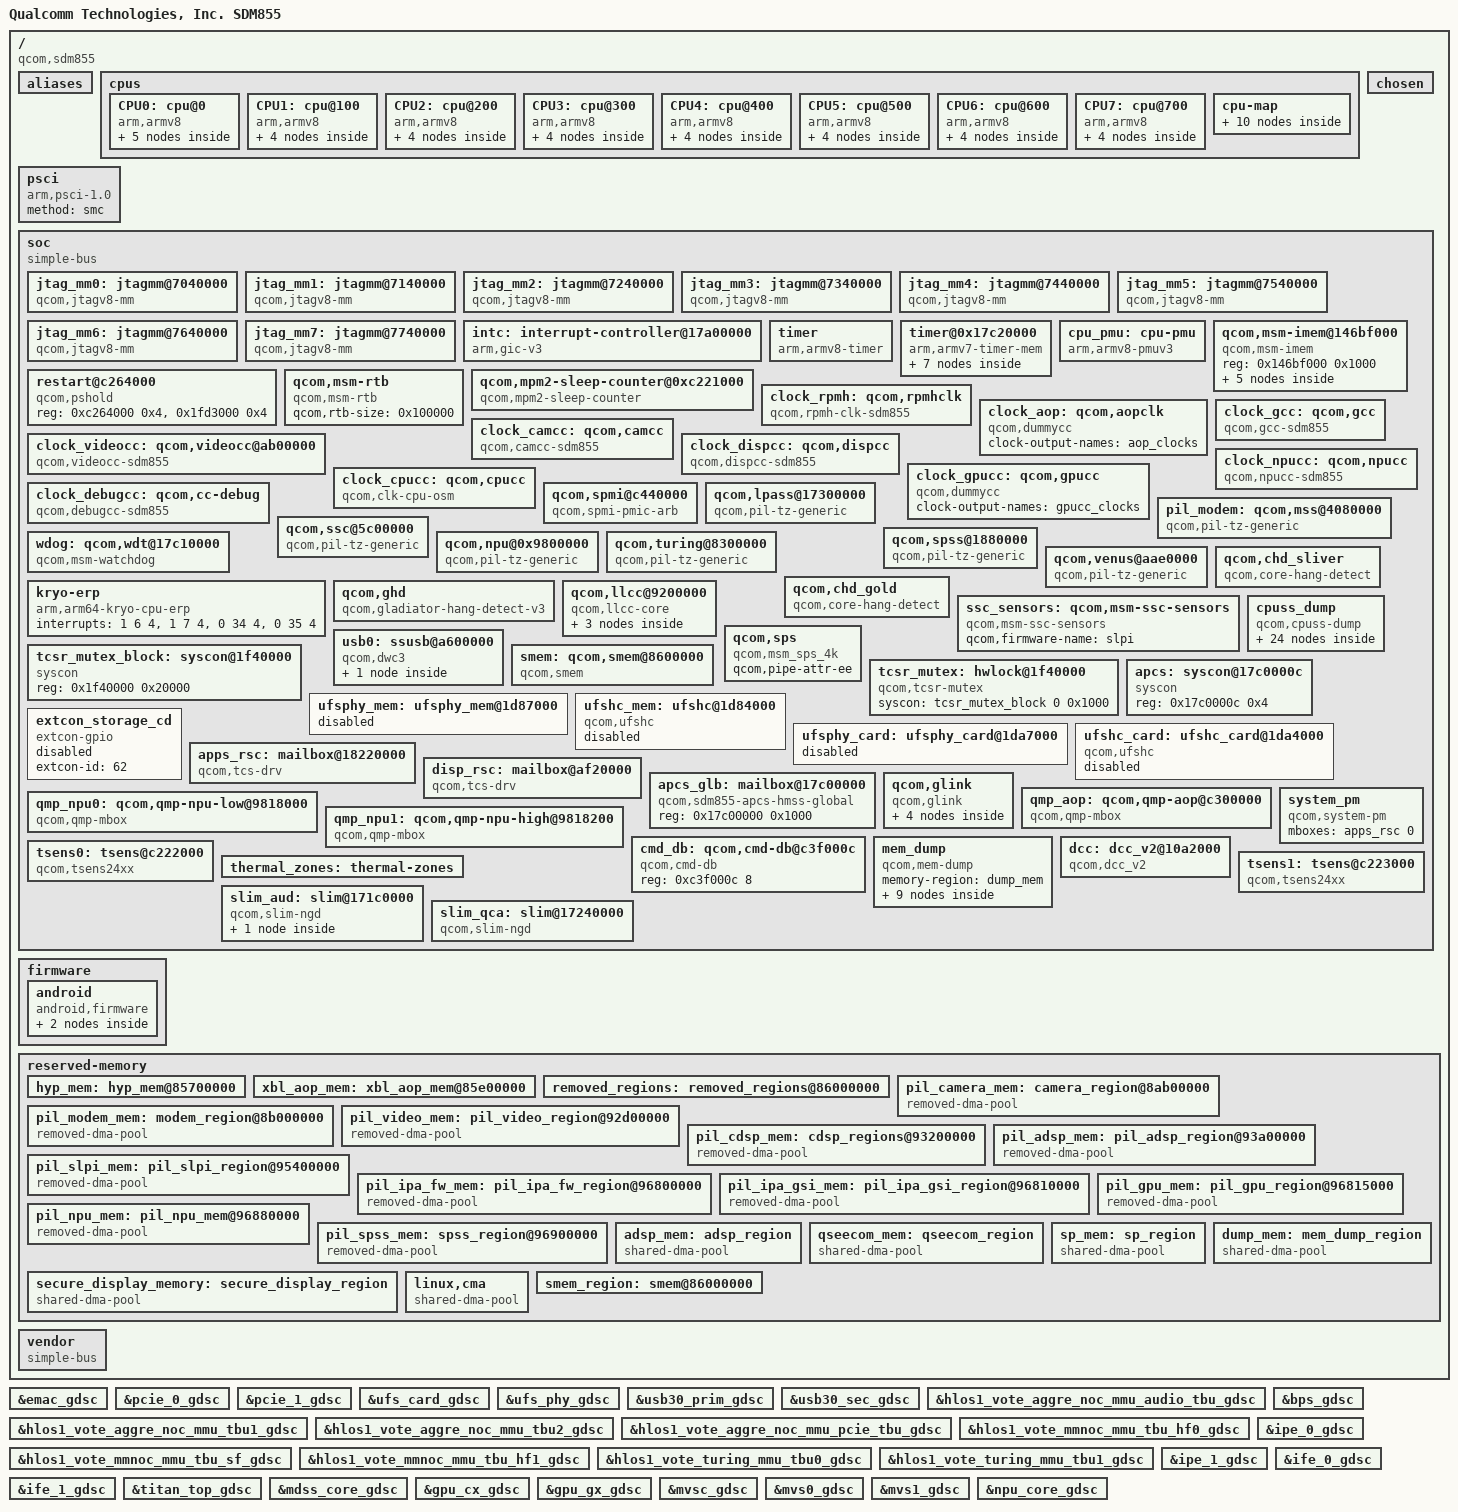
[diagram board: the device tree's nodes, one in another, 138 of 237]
/* Copyright (c) 2017, The Linux Foundation. All rights reserved.
 *
 * This program is free software; you can redistribute it and/or modify
 * it under the terms of the GNU General Public License version 2 and
 * only version 2 as published by the Free Software Foundation.
 *
 * This program is distributed in the hope that it will be useful,
 * but WITHOUT ANY WARRANTY; without even the implied warranty of
 * MERCHANTABILITY or FITNESS FOR A PARTICULAR PURPOSE.  See the
 * GNU General Public License for more details.
 */

#include "skeleton64.dtsi"
#include <dt-bindings/clock/qcom,gcc-sdm855.h>
#include <dt-bindings/clock/qcom,camcc-sdm855.h>
#include <dt-bindings/clock/qcom,dispcc-sdm855.h>
#include <dt-bindings/clock/qcom,gpucc-sdm855.h>
#include <dt-bindings/clock/qcom,videocc-sdm855.h>
#include <dt-bindings/clock/qcom,cpucc-sdm855.h>
#include <dt-bindings/clock/qcom,npucc-sdm855.h>
#include <dt-bindings/clock/qcom,rpmh.h>
#include <dt-bindings/clock/qcom,aop-qmp.h>
#include <dt-bindings/regulator/qcom,rpmh-regulator.h>
#include <dt-bindings/interrupt-controller/arm-gic.h>
#include <dt-bindings/soc/qcom,tcs-mbox.h>
#include <dt-bindings/soc/qcom,dcc_v2.h>

/ {
	model = "Qualcomm Technologies, Inc. SDM855";
	compatible = "qcom,sdm855";
	qcom,msm-id = <339 0x0>;
	interrupt-parent = <&intc>;

	aliases {
		ufshc1 = &ufshc_mem; /* Embedded UFS slot */
		ufshc2 = &ufshc_card; /* Removable UFS slot */
	};

	aliases {
		serial0 = &qupv3_se12_2uart;
		hsuart0 = &qupv3_se17_4uart;
	};

	cpus {
		#address-cells = <2>;
		#size-cells = <0>;

		CPU0: cpu@0 {
			device_type = "cpu";
			compatible = "arm,armv8";
			reg = <0x0 0x0>;
			enable-method = "psci";
			cache-size = <0x8000>;
			next-level-cache = <&L2_0>;
			L2_0: l2-cache {
			      compatible = "arm,arch-cache";
			      cache-size = <0x20000>;
			      cache-level = <2>;
			      next-level-cache = <&L3_0>;

				L3_0: l3-cache {
				      compatible = "arm,arch-cache";
				      cache-size = <0x200000>;
				      cache-level = <3>;
				};
			};

			L1_I_0: l1-icache {
				compatible = "arm,arch-cache";
				qcom,dump-size = <0xa000>;
			};

			L1_D_0: l1-dcache {
				compatible = "arm,arch-cache";
				qcom,dump-size = <0xa000>;
			};

			L1_TLB_0: l1-tlb {
				qcom,dump-size = <0x3000>;
			};
		};

		CPU1: cpu@100 {
			device_type = "cpu";
			compatible = "arm,armv8";
			reg = <0x0 0x100>;
			enable-method = "psci";
			cache-size = <0x8000>;
			next-level-cache = <&L2_1>;
			L2_1: l2-cache {
			      compatible = "arm,arch-cache";
			      cache-size = <0x20000>;
			      cache-level = <2>;
			      next-level-cache = <&L3_0>;
			};

			L1_I_100: l1-icache {
				compatible = "arm,arch-cache";
				qcom,dump-size = <0xa000>;
			};

			L1_D_100: l1-dcache {
				compatible = "arm,arch-cache";
				qcom,dump-size = <0xa000>;
			};

			L1_TLB_100: l1-tlb {
				qcom,dump-size = <0x3000>;
			};
		};

		CPU2: cpu@200 {
			device_type = "cpu";
			compatible = "arm,armv8";
			reg = <0x0 0x200>;
			enable-method = "psci";
			cache-size = <0x8000>;
			next-level-cache = <&L2_2>;
			L2_2: l2-cache {
			      compatible = "arm,arch-cache";
			      cache-size = <0x20000>;
			      cache-level = <2>;
			      next-level-cache = <&L3_0>;
			};

			L1_I_200: l1-icache {
				compatible = "arm,arch-cache";
				qcom,dump-size = <0xa000>;
			};

			L1_D_200: l1-dcache {
				compatible = "arm,arch-cache";
				qcom,dump-size = <0xa000>;
			};

			L1_TLB_200: l1-tlb {
				qcom,dump-size = <0x3000>;
			};
		};

		CPU3: cpu@300 {
			device_type = "cpu";
			compatible = "arm,armv8";
			reg = <0x0 0x300>;
			enable-method = "psci";
			cache-size = <0x8000>;
			next-level-cache = <&L2_3>;
			L2_3: l2-cache {
			      compatible = "arm,arch-cache";
			      cache-size = <0x20000>;
			      cache-level = <2>;
			      next-level-cache = <&L3_0>;
			};

			L1_I_300: l1-icache {
				compatible = "arm,arch-cache";
				qcom,dump-size = <0xa000>;
			};

			L1_D_300: l1-dcache {
				compatible = "arm,arch-cache";
				qcom,dump-size = <0xa000>;
			};

			L1_TLB_300: l1-tlb {
				qcom,dump-size = <0x3000>;
			};
		};

		CPU4: cpu@400 {
			device_type = "cpu";
			compatible = "arm,armv8";
			reg = <0x0 0x400>;
			enable-method = "psci";
			cache-size = <0x20000>;
			next-level-cache = <&L2_4>;
			L2_4: l2-cache {
			      compatible = "arm,arch-cache";
			      cache-size = <0x40000>;
			      cache-level = <2>;
			      next-level-cache = <&L3_0>;
			};

			L1_I_400: l1-icache {
				compatible = "arm,arch-cache";
				qcom,dump-size = <0x14000>;
			};

			L1_D_400: l1-dcache {
				compatible = "arm,arch-cache";
				qcom,dump-size = <0x14000>;
			};

			L1_TLB_400: l1-tlb {
				qcom,dump-size = <0x3c00>;
			};
		};

		CPU5: cpu@500 {
			device_type = "cpu";
			compatible = "arm,armv8";
			reg = <0x0 0x500>;
			enable-method = "psci";
			cache-size = <0x20000>;
			next-level-cache = <&L2_5>;
			L2_5: l2-cache {
			      compatible = "arm,arch-cache";
			      cache-size = <0x40000>;
			      cache-level = <2>;
			      next-level-cache = <&L3_0>;
			};

			L1_I_500: l1-icache {
				compatible = "arm,arch-cache";
				qcom,dump-size = <0x14000>;
			};

			L1_D_500: l1-dcache {
				compatible = "arm,arch-cache";
				qcom,dump-size = <0x14000>;
			};

			L1_TLB_500: l1-tlb {
				qcom,dump-size = <0x3c00>;
			};
		};

		CPU6: cpu@600 {
			device_type = "cpu";
			compatible = "arm,armv8";
			reg = <0x0 0x600>;
			enable-method = "psci";
			cache-size = <0x20000>;
			next-level-cache = <&L2_6>;
			L2_6: l2-cache {
			      compatible = "arm,arch-cache";
			      cache-size = <0x40000>;
			      cache-level = <2>;
			      next-level-cache = <&L3_0>;
			};

			L1_I_600: l1-icache {
				compatible = "arm,arch-cache";
				qcom,dump-size = <0x14000>;
			};

			L1_D_600: l1-dcache {
				compatible = "arm,arch-cache";
				qcom,dump-size = <0x14000>;
			};

			L1_TLB_600: l1-tlb {
				qcom,dump-size = <0x3c00>;
			};
		};

		CPU7: cpu@700 {
			device_type = "cpu";
			compatible = "arm,armv8";
			reg = <0x0 0x700>;
			enable-method = "psci";
			cache-size = <0x20000>;
			next-level-cache = <&L2_7>;
			L2_7: l2-cache {
			      compatible = "arm,arch-cache";
			      cache-size = <0x80000>;
			      cache-level = <2>;
			      next-level-cache = <&L3_0>;
			};

			L1_I_700: l1-icache {
				compatible = "arm,arch-cache";
				qcom,dump-size = <0x14000>;
			};

			L1_D_700: l1-dcache {
				compatible = "arm,arch-cache";
				qcom,dump-size = <0x14000>;
			};

			L1_TLB_700: l1-tlb {
				qcom,dump-size = <0x3c00>;
			};
		};

		cpu-map {
			cluster0 {
				core0 {
					cpu = <&CPU0>;
				};

				core1 {
					cpu = <&CPU1>;
				};

				core2 {
					cpu = <&CPU2>;
				};

				core3 {
					cpu = <&CPU3>;
				};
			};

			cluster1 {
				core0 {
					cpu = <&CPU4>;
				};

				core1 {
					cpu = <&CPU5>;
				};

				core2 {
					cpu = <&CPU6>;
				};

				core3 {
					cpu = <&CPU7>;
				};
			};
		};
	};

	psci {
		compatible = "arm,psci-1.0";
		method = "smc";
	};

	chosen {
		bootargs = "rcupdate.rcu_expedited=1 rcu_nocbs=0-7";
	};

	soc: soc { };

	firmware: firmware {
		android {
			compatible = "android,firmware";
			fstab {
				compatible = "android,fstab";
				vendor {
					compatible = "android,vendor";
					dev = "/dev/block/platform/soc/1d84000.ufshc/by-name/vendor";
					type = "ext4";
					mnt_flags = "ro,barrier=1,discard";
					fsmgr_flags = "wait,slotselect";
					status = "ok";
				};
			};
		};
	};

	reserved-memory {
		#address-cells = <2>;
		#size-cells = <2>;
		ranges;

		hyp_mem: hyp_mem@85700000 {
			no-map;
			reg = <0x0 0x85700000 0x0 0x600000>;
		};

		xbl_aop_mem: xbl_aop_mem@85e00000 {
			no-map;
			reg = <0x0 0x85e00000 0x0 0x140000>;
		};

		removed_regions: removed_regions@86000000 {
			no-map;
			reg = <0x0 0x86200000 0x0 0x2d00000>;
		};

		pil_camera_mem: camera_region@8ab00000 {
			compatible = "removed-dma-pool";
			no-map;
			reg = <0x0 0x8ab00000 0x0 0x500000>;
		};

		pil_modem_mem: modem_region@8b000000 {
			compatible = "removed-dma-pool";
			no-map;
			reg = <0x0 0x8b000000 0x0 0x7D00000>;
		};

		pil_video_mem: pil_video_region@92d00000 {
			compatible = "removed-dma-pool";
			no-map;
			reg = <0x0 0x92d00000 0x0 0x500000>;
		};

		pil_cdsp_mem: cdsp_regions@93200000 {
			compatible = "removed-dma-pool";
			no-map;
			reg = <0x0 0x93200000 0x0 0x800000>;
		};

		pil_adsp_mem: pil_adsp_region@93a00000 {
			compatible = "removed-dma-pool";
			no-map;
			reg = <0x0 0x93a00000 0x0 0x1a00000>;
		};

		pil_slpi_mem: pil_slpi_region@95400000 {
			compatible = "removed-dma-pool";
			no-map;
			reg = <0x0 0x95400000 0x0 0x1400000>;
		};

		pil_ipa_fw_mem: pil_ipa_fw_region@96800000 {
			compatible = "removed-dma-pool";
			no-map;
			reg = <0x0 0x96800000 0x0 0x10000>;
		};

		pil_ipa_gsi_mem: pil_ipa_gsi_region@96810000 {
			compatible = "removed-dma-pool";
			no-map;
			reg = <0x0 0x96810000 0x0 0x5000>;
		};

		pil_gpu_mem: pil_gpu_region@96815000 {
			compatible = "removed-dma-pool";
			no-map;
			reg = <0x0 0x96815000 0x0 0x1000>;
		};

		pil_npu_mem: pil_npu_mem@96880000 {
			compatible = "removed-dma-pool";
			no-map;
			reg = <0x0 0x96880000 0x0 0x80000>;
		};

		pil_spss_mem: spss_region@96900000 {
			compatible = "removed-dma-pool";
			no-map;
			reg = <0x0 0x96900000 0x0 0x100000>;
		};

		adsp_mem: adsp_region {
			compatible = "shared-dma-pool";
			alloc-ranges = <0x0 0x00000000 0x0 0xffffffff>;
			reusable;
			alignment = <0x0 0x400000>;
			size = <0x0 0xc00000>;
		};

		qseecom_mem: qseecom_region {
			compatible = "shared-dma-pool";
			alloc-ranges = <0x0 0x00000000 0x0 0xffffffff>;
			reusable;
			alignment = <0x0 0x400000>;
			size = <0x0 0x1400000>;
		};

		sp_mem: sp_region {  /* SPSS-HLOS ION shared mem */
			compatible = "shared-dma-pool";
			alloc-ranges = <0x0 0x00000000 0x0 0xffffffff>;
			reusable;
			alignment = <0x0 0x400000>;
			size = <0x0 0x800000>;
		};

		secure_display_memory: secure_display_region {
			compatible = "shared-dma-pool";
			alloc-ranges = <0x0 0x00000000 0x0 0xffffffff>;
			reusable;
			alignment = <0x0 0x400000>;
			size = <0x0 0x5c00000>;
		};

		dump_mem: mem_dump_region {
			compatible = "shared-dma-pool";
			reusable;
			size = <0 0x2400000>;
		};

		/* global autoconfigured region for contiguous allocations */
		linux,cma {
			compatible = "shared-dma-pool";
			alloc-ranges = <0x0 0x00000000 0x0 0xffffffff>;
			reusable;
			alignment = <0x0 0x400000>;
			size = <0x0 0x2000000>;
			linux,cma-default;
		};

		smem_region: smem@86000000 {
			no-map;
			reg = <0x0 0x86000000 0x0 0x200000>;
		};
	};

	vendor: vendor {
		#address-cells = <1>;
		#size-cells = <1>;
		ranges = <0 0 0 0xffffffff>;
		compatible = "simple-bus";
	};
};

#include "sdm855-gdsc.dtsi"

#include "sdm855-sde-pll.dtsi"
#include "sdm855-sde.dtsi"
#include "sdm855-sde-display.dtsi"

&soc {
	#address-cells = <1>;
	#size-cells = <1>;
	ranges = <0 0 0 0xffffffff>;
	compatible = "simple-bus";

	jtag_mm0: jtagmm@7040000 {
		compatible = "qcom,jtagv8-mm";
		reg = <0x7040000 0x1000>;
		reg-names = "etm-base";

		clocks = <&clock_aop QDSS_CLK>;
		clock-names = "core_clk";

		qcom,coresight-jtagmm-cpu = <&CPU0>;
	};

	jtag_mm1: jtagmm@7140000 {
		compatible = "qcom,jtagv8-mm";
		reg = <0x7140000 0x1000>;
		reg-names = "etm-base";

		clocks = <&clock_aop QDSS_CLK>;
		clock-names = "core_clk";

		qcom,coresight-jtagmm-cpu = <&CPU1>;
	};

	jtag_mm2: jtagmm@7240000 {
		compatible = "qcom,jtagv8-mm";
		reg = <0x7240000 0x1000>;
		reg-names = "etm-base";

		clocks = <&clock_aop QDSS_CLK>;
		clock-names = "core_clk";

		qcom,coresight-jtagmm-cpu = <&CPU2>;
	};

	jtag_mm3: jtagmm@7340000 {
		compatible = "qcom,jtagv8-mm";
		reg = <0x7340000 0x1000>;
		reg-names = "etm-base";

		clocks = <&clock_aop QDSS_CLK>;
		clock-names = "core_clk";

		qcom,coresight-jtagmm-cpu = <&CPU3>;
	};

	jtag_mm4: jtagmm@7440000 {
		compatible = "qcom,jtagv8-mm";
		reg = <0x7440000 0x1000>;
		reg-names = "etm-base";

		clocks = <&clock_aop QDSS_CLK>;
		clock-names = "core_clk";

		qcom,coresight-jtagmm-cpu = <&CPU4>;
	};

	jtag_mm5: jtagmm@7540000 {
		compatible = "qcom,jtagv8-mm";
		reg = <0x7540000 0x1000>;
		reg-names = "etm-base";

		clocks = <&clock_aop QDSS_CLK>;
		clock-names = "core_clk";

		qcom,coresight-jtagmm-cpu = <&CPU5>;
	};

	jtag_mm6: jtagmm@7640000 {
		compatible = "qcom,jtagv8-mm";
		reg = <0x7640000 0x1000>;
		reg-names = "etm-base";

		clocks = <&clock_aop QDSS_CLK>;
		clock-names = "core_clk";

		qcom,coresight-jtagmm-cpu = <&CPU6>;
	};

	jtag_mm7: jtagmm@7740000 {
		compatible = "qcom,jtagv8-mm";
		reg = <0x7740000 0x1000>;
		reg-names = "etm-base";

		clocks = <&clock_aop QDSS_CLK>;
		clock-names = "core_clk";

		qcom,coresight-jtagmm-cpu = <&CPU7>;
	};

	intc: interrupt-controller@17a00000 {
		compatible = "arm,gic-v3";
		#interrupt-cells = <3>;
		interrupt-controller;
		#redistributor-regions = <1>;
		redistributor-stride = <0x0 0x20000>;
		reg = <0x17a00000 0x10000>,     /* GICD */
		      <0x17a60000 0x100000>;    /* GICR * 8 */
		interrupts = <1 9 4>;
	};

	timer {
		compatible = "arm,armv8-timer";
		interrupts = <1 1 0xf08>,
			     <1 2 0xf08>,
			     <1 3 0xf08>,
			     <1 0 0xf08>;
		clock-frequency = <19200000>;
	};

	timer@0x17c20000{
		#address-cells = <1>;
		#size-cells = <1>;
		ranges;
		compatible = "arm,armv7-timer-mem";
		reg = <0x17c20000 0x1000>;
		clock-frequency = <19200000>;

		frame@0x17c21000 {
			frame-number = <0>;
			interrupts = <0 7 0x4>,
				     <0 6 0x4>;
			reg = <0x17c21000 0x1000>,
			      <0x17c22000 0x1000>;
		};

		frame@17c23000 {
			frame-number = <1>;
			interrupts = <0 8 0x4>;
			reg = <0x17c23000 0x1000>;
			status = "disabled";
		};

		frame@17c25000 {
			frame-number = <2>;
			interrupts = <0 9 0x4>;
			reg = <0x17c25000 0x1000>;
			status = "disabled";
		};

		frame@17c27000 {
			frame-number = <3>;
			interrupts = <0 10 0x4>;
			reg = <0x17c26000 0x1000>;
			status = "disabled";
		};

		frame@17c29000 {
			frame-number = <4>;
			interrupts = <0 11 0x4>;
			reg = <0x17c29000 0x1000>;
			status = "disabled";
		};

		frame@17c2b000 {
			frame-number = <5>;
			interrupts = <0 12 0x4>;
			reg = <0x17c2b000 0x1000>;
			status = "disabled";
		};

		frame@17c2d000 {
			frame-number = <6>;
			interrupts = <0 13 0x4>;
			reg = <0x17c2d000 0x1000>;
			status = "disabled";
		};
	};

	cpu_pmu: cpu-pmu {
		compatible = "arm,armv8-pmuv3";
		qcom,irq-is-percpu;
		interrupts = <1 5 4>;
	};

	qcom,msm-imem@146bf000 {
		compatible = "qcom,msm-imem";
		reg = <0x146bf000 0x1000>;
		ranges = <0x0 0x146bf000 0x1000>;
		#address-cells = <1>;
		#size-cells = <1>;

		mem_dump_table@10 {
			compatible = "qcom,msm-imem-mem_dump_table";
			reg = <0x10 8>;
		};

		restart_reason@65c {
			compatible = "qcom,msm-imem-restart_reason";
			reg = <0x65c 4>;
		};

		boot_stats@6b0 {
			compatible = "qcom,msm-imem-boot_stats";
			reg = <0x6b0 32>;
		};

		kaslr_offset@6d0 {
			compatible = "qcom,msm-imem-kaslr_offset";
			reg = <0x6d0 12>;
		};

		pil@94c {
			compatible = "qcom,msm-imem-pil";
			reg = <0x94c 200>;
		};
	};

	restart@c264000 {
		compatible = "qcom,pshold";
		reg = <0xc264000 0x4>,
		      <0x1fd3000 0x4>;
		reg-names = "pshold-base", "tcsr-boot-misc-detect";
	};

	qcom,msm-rtb {
		compatible = "qcom,msm-rtb";
		qcom,rtb-size = <0x100000>;
	};

	qcom,mpm2-sleep-counter@0xc221000 {
		compatible = "qcom,mpm2-sleep-counter";
		reg = <0xc221000 0x1000>;
		clock-frequency = <32768>;
	};

	clock_rpmh: qcom,rpmhclk {
		compatible = "qcom,rpmh-clk-sdm855";
		mboxes = <&apps_rsc 0>;
		mbox-names = "apps";
		#clock-cells = <1>;
	};

	clock_aop: qcom,aopclk {
		compatible = "qcom,dummycc";
		clock-output-names = "aop_clocks";
		#clock-cells = <1>;
		#reset-cells = <1>;
	};

	clock_gcc: qcom,gcc {
		compatible = "qcom,gcc-sdm855", "syscon";
		reg = <0x100000 0x1f0000>;
		reg-names = "cc_base";
		vdd_cx-supply = <&pm855l_s6_level>;
		vdd_cx_ao-supply = <&pm855l_s6_level_ao>;
		vdd_mm-supply = <&pm855l_s5_level>;
		#clock-cells = <1>;
		#reset-cells = <1>;
	};

	clock_videocc: qcom,videocc@ab00000 {
		compatible = "qcom,videocc-sdm855", "syscon";
		reg = <0xab00000 0x10000>;
		reg-names = "cc_base";
		vdd_mm-supply = <&pm855l_s5_level>;
		clock-names = "cfg_ahb_clk";
		clocks = <&clock_gcc GCC_VIDEO_AHB_CLK>;
		#clock-cells = <1>;
		#reset-cells = <1>;
	};

	clock_camcc: qcom,camcc {
		compatible = "qcom,camcc-sdm855", "syscon";
		reg = <0xad00000 0x10000>;
		reg-names = "cc_base";
		vdd_mx-supply = <&pm855l_s4_level>;
		vdd_mm-supply = <&pm855l_s5_level>;
		clock-names = "cfg_ahb_clk";
		clocks = <&clock_gcc GCC_CAMERA_AHB_CLK>;
		#clock-cells = <1>;
	};

	clock_dispcc: qcom,dispcc {
		compatible = "qcom,dispcc-sdm855", "syscon";
		reg = <0xaf00000 0x20000>;
		reg-names = "cc_base";
		vdd_mm-supply = <&pm855l_s5_level>;
		clock-names = "cfg_ahb_clk";
		clocks = <&clock_gcc GCC_DISP_AHB_CLK>;
		#clock-cells = <1>;
		#reset-cells = <1>;
	};

	clock_npucc: qcom,npucc {
		compatible = "qcom,npucc-sdm855", "syscon";
		reg = <0x9910000 0x10000>;
		reg-names = "cc_base";
		vdd_cx-supply = <&pm855l_s6_level>;
		#clock-cells = <1>;
		#reset-cells = <1>;
	};

	clock_gpucc: qcom,gpucc {
		compatible = "qcom,dummycc";
		clock-output-names = "gpucc_clocks";
		#clock-cells = <1>;
		#reset-cells = <1>;
	};

	clock_cpucc: qcom,cpucc {
		compatible = "qcom,clk-cpu-osm";
		reg = <0x18321000 0x1400>,
			<0x18323000 0x1400>,
			<0x18325800 0x1400>,
			<0x18327800 0x1400>;
		reg-names = "osm_l3_base", "osm_pwrcl_base",
			"osm_perfcl_base", "osm_perfpcl_base";

		#clock-cells = <1>;
	};

	clock_debugcc: qcom,cc-debug {
		compatible = "qcom,debugcc-sdm855";
		qcom,gcc = <&clock_gcc>;
		qcom,videocc = <&clock_videocc>;
		qcom,camcc = <&clock_camcc>;
		qcom,dispcc = <&clock_dispcc>;
		qcom,npucc = <&clock_npucc>;
		clock-names = "xo_clk_src";
		clocks = <&clock_rpmh RPMH_CXO_CLK>;
		#clock-cells = <1>;
	};

	qcom,spmi@c440000 {
		compatible = "qcom,spmi-pmic-arb";
		reg = <0xc440000 0x1100>,
		      <0xc600000 0x2000000>,
		      <0xe600000 0x100000>,
		      <0xe700000 0xa0000>,
		      <0xc40a000 0x26000>;
		reg-names = "core", "chnls", "obsrvr", "intr", "cnfg";
		interrupt-names = "periph_irq";
		interrupts = <GIC_SPI 481 IRQ_TYPE_NONE>;
		qcom,ee = <0>;
		qcom,channel = <0>;
		#address-cells = <2>;
		#size-cells = <0>;
		interrupt-controller;
		#interrupt-cells = <4>;
		cell-index = <0>;
	};

	pil_modem: qcom,mss@4080000 {
		compatible = "qcom,pil-tz-generic";
		reg = <0x4080000 0x100>;

		clocks = <&clock_rpmh RPMH_CXO_CLK>;
		clock-names = "xo";
		qcom,proxy-clock-names = "xo";

		vdd_cx-supply = <&pm855l_s6_level>;
		qcom,vdd_cx-uV-uA = <RPMH_REGULATOR_LEVEL_TURBO 100000>;
		vdd_mss-supply = <&pm855_s1_level>;
		qcom,vdd_mss-uV-uA = <RPMH_REGULATOR_LEVEL_TURBO 100000>;
		qcom,proxy-reg-names = "vdd_cx", "vdd_mss";

		qcom,firmware-name = "modem";
		memory-region = <&pil_modem_mem>;
		qcom,proxy-timeout-ms = <10000>;
		qcom,sysmon-id = <0>;
		qcom,ssctl-instance-id = <0x12>;
		qcom,pas-id = <0>;
		qcom,smem-id = <421>;

		/* Inputs from mss */
		interrupts-extended = <&intc 0 266 1>,
				<&modem_smp2p_in 0 0>,
				<&modem_smp2p_in 2 0>,
				<&modem_smp2p_in 1 0>,
				<&modem_smp2p_in 3 0>,
				<&modem_smp2p_in 7 0>;

		interrupt-names = "qcom,wdog",
				"qcom,err-fatal",
				"qcom,proxy-unvote",
				"qcom,err-ready",
				"qcom,stop-ack",
				"qcom,shutdown-ack";

		/* Outputs to mss */
		qcom,smem-states = <&modem_smp2p_out 0>;
		qcom,smem-state-names = "qcom,force-stop";
	};

	qcom,lpass@17300000 {
		compatible = "qcom,pil-tz-generic";
		reg = <0x17300000 0x00100>;

		vdd_cx-supply = <&pm855l_s6_level>;
		qcom,vdd_cx-uV-uA = <RPMH_REGULATOR_LEVEL_TURBO 0>;
		qcom,proxy-reg-names = "vdd_cx";

		clocks = <&clock_rpmh RPMH_CXO_CLK>;
		clock-names = "xo";
		qcom,proxy-clock-names = "xo";

		qcom,pas-id = <1>;
		qcom,proxy-timeout-ms = <10000>;
		qcom,smem-id = <423>;
		qcom,sysmon-id = <1>;
		qcom,ssctl-instance-id = <0x14>;
		qcom,firmware-name = "adsp";
		memory-region = <&pil_adsp_mem>;

		/* Inputs from lpass */
		interrupts-extended = <&intc 0 162 1>,
				<&adsp_smp2p_in 0 0>,
				<&adsp_smp2p_in 2 0>,
				<&adsp_smp2p_in 1 0>,
				<&adsp_smp2p_in 3 0>;

		interrupt-names = "qcom,wdog",
				"qcom,err-fatal",
				"qcom,proxy-unvote",
				"qcom,err-ready",
				"qcom,stop-ack";

		/* Outputs to lpass */
		qcom,smem-states = <&adsp_smp2p_out 0>;
		qcom,smem-state-names = "qcom,force-stop";
	};

	qcom,ssc@5c00000 {
		compatible = "qcom,pil-tz-generic";
		reg = <0x5c00000 0x4000>;

		vdd_cx-supply = <&pm855_l8_level>;
		qcom,vdd_cx-uV-uA = <RPMH_REGULATOR_LEVEL_TURBO 0>;
		vdd_mx-supply = <&pm855_l4_level>;
		qcom,vdd_mx-uV-uA = <RPMH_REGULATOR_LEVEL_TURBO 0>;

		qcom,proxy-reg-names = "vdd_cx", "vdd_mx";
		qcom,keep-proxy-regs-on;

		clocks = <&clock_rpmh RPMH_CXO_CLK>;
		clock-names = "xo";
		qcom,proxy-clock-names = "xo";

		qcom,pas-id = <12>;
		qcom,proxy-timeout-ms = <10000>;
		qcom,smem-id = <424>;
		qcom,sysmon-id = <3>;
		qcom,ssctl-instance-id = <0x16>;
		qcom,firmware-name = "slpi";
		status = "ok";
		memory-region = <&pil_slpi_mem>;

		/* Inputs from ssc */
		interrupts-extended = <&intc 0 494 1>,
				<&dsps_smp2p_in 0 0>,
				<&dsps_smp2p_in 2 0>,
				<&dsps_smp2p_in 1 0>,
				<&dsps_smp2p_in 3 0>;

		interrupt-names = "qcom,wdog",
				"qcom,err-fatal",
				"qcom,proxy-unvote",
				"qcom,err-ready",
				"qcom,stop-ack";

		/* Outputs to ssc */
		qcom,smem-states = <&dsps_smp2p_out 0>;
		qcom,smem-state-names = "qcom,force-stop";
	};

	qcom,spss@1880000 {
		compatible = "qcom,pil-tz-generic";
		reg = <0x188101c 0x4>,
		      <0x1881024 0x4>,
		      <0x1881028 0x4>,
		      <0x188103c 0x4>,
		      <0x1882014 0x4>;
		reg-names = "sp2soc_irq_status", "sp2soc_irq_clr",
			    "sp2soc_irq_mask", "rmb_err", "rmb_err_spare2";
		interrupts = <0 352 1>;

		vdd_cx-supply = <&pm855l_s6_level>;
		qcom,proxy-reg-names = "vdd_cx";
		qcom,vdd_cx-uV-uA = <RPMH_REGULATOR_LEVEL_TURBO 100000>;
		vdd_mx-supply = <&pm855l_s4_level>;
		vdd_mx-uV = <RPMH_REGULATOR_LEVEL_TURBO 100000>;

		clocks = <&clock_rpmh RPMH_CXO_CLK>;
		clock-names = "xo";
		qcom,proxy-clock-names = "xo";
		qcom,pil-generic-irq-handler;
		status = "ok";

		qcom,pas-id = <14>;
		qcom,proxy-timeout-ms = <10000>;
		qcom,firmware-name = "spss";
		memory-region = <&pil_spss_mem>;
		qcom,spss-scsr-bits = <24 25>;
	};

	wdog: qcom,wdt@17c10000{
		compatible = "qcom,msm-watchdog";
		reg = <0x17c10000 0x1000>;
		reg-names = "wdt-base";
		interrupts = <0 0 0>, <0 1 0>;
		qcom,bark-time = <11000>;
		qcom,pet-time = <9360>;
		qcom,ipi-ping;
		qcom,wakeup-enable;
	};

	qcom,npu@0x9800000 {
		compatible = "qcom,pil-tz-generic";
		reg = <0x9800000 0x800000>;

		clocks = <&clock_npucc NPU_CC_XO_CLK>,
			<&clock_npucc NPU_CC_ARMWIC_CORE_CLK>,
			<&clock_npucc NPU_CC_CAL_DP_CLK_SRC>,
			<&clock_npucc NPU_CC_CAL_DP_CLK>,
			<&clock_npucc NPU_CC_CAL_DP_CDC_CLK>,
			<&clock_npucc NPU_CC_SLEEP_CLK>,
			<&clock_npucc NPU_CC_COMP_NOC_AXI_CLK>,
			<&clock_npucc NPU_CC_CONF_NOC_AHB_CLK>,
			<&clock_npucc NPU_CC_NPU_CORE_CLK_SRC>,
			<&clock_npucc NPU_CC_NPU_CORE_CLK>,
			<&clock_npucc NPU_CC_NPU_CORE_APB_CLK>,
			<&clock_npucc NPU_CC_NPU_CORE_ATB_CLK>,
			<&clock_npucc NPU_CC_NPU_CORE_CTI_CLK>,
			<&clock_npucc NPU_CC_BWMON_CLK>,
			<&clock_npucc NPU_CC_QTIMER_CORE_CLK>,
			<&clock_npucc NPU_CC_BTO_CORE_CLK>;

		clock-names = "xo", "armwic", "cal_dp_src", "cal_dp",
			"cal_dp_cdc", "sleep", "noc_axi", "noc_ahb",
			"core_src", "core", "apb", "atb", "cti", "bwmon",
			"qtimer", "bto";

		qcom,proxy-clock-names = "xo", "armwic", "cal_dp_src", "cal_dp",
			"cal_dp_cdc", "sleep", "noc_axi", "noc_ahb",
			"core_src", "core", "apb", "atb", "cti", "bwmon",
			"qtimer", "bto";

		vdd-supply = <&npu_core_gdsc>;
		vdd_cx-supply = <&pm855l_s6_level>;
		qcom,proxy-reg-names ="vdd", "vdd_cx";
		qcom,vdd_cx-uV-uA = <RPMH_REGULATOR_LEVEL_TURBO 100000>;

		status = "ok";

		qcom,pas-id = <23>;
		qcom,proxy-timeout-ms = <10000>;
		qcom,firmware-name = "npu";
		memory-region = <&pil_npu_mem>;
	};

	qcom,turing@8300000 {
		compatible = "qcom,pil-tz-generic";
		reg = <0x8300000 0x100000>;

		vdd_cx-supply = <&pm855l_s6_level>;
		qcom,proxy-reg-names = "vdd_cx";
		qcom,vdd_cx-uV-uA = <RPMH_REGULATOR_LEVEL_TURBO 100000>;

		clocks = <&clock_rpmh RPMH_CXO_CLK>;
		clock-names = "xo";
		qcom,proxy-clock-names = "xo";

		qcom,pas-id = <18>;
		qcom,proxy-timeout-ms = <10000>;
		qcom,smem-id = <601>;
		qcom,sysmon-id = <7>;
		qcom,ssctl-instance-id = <0x17>;
		qcom,firmware-name = "cdsp";
		memory-region = <&pil_cdsp_mem>;

		/* Inputs from turing */
		interrupts-extended = <&intc 0 578 1>,
				<&cdsp_smp2p_in 0 0>,
				<&cdsp_smp2p_in 2 0>,
				<&cdsp_smp2p_in 1 0>,
				<&cdsp_smp2p_in 3 0>;

		interrupt-names = "qcom,wdog",
				"qcom,err-fatal",
				"qcom,proxy-unvote",
				"qcom,err-ready",
				"qcom,stop-ack";

		/* Outputs to turing */
		qcom,smem-states = <&cdsp_smp2p_out 0>;
		qcom,smem-state-names = "qcom,force-stop";
	};

	qcom,venus@aae0000 {
		compatible = "qcom,pil-tz-generic";
		reg = <0xaae0000 0x4000>;

		vdd-supply = <&mvsc_gdsc>;
		qcom,proxy-reg-names = "vdd";

		clocks = <&clock_videocc VIDEO_CC_XO_CLK>,
			<&clock_videocc VIDEO_CC_MVSC_CORE_CLK>,
			<&clock_videocc VIDEO_CC_IRIS_AHB_CLK>;
		clock-names = "xo", "core", "ahb";
		qcom,proxy-clock-names = "xo",  "core", "ahb";

		qcom,core-freq = <200000000>;
		qcom,ahb-freq = <200000000>;

		qcom,pas-id = <9>;
		qcom,msm-bus,name = "pil-venus";
		qcom,msm-bus,num-cases = <2>;
		qcom,msm-bus,num-paths = <1>;
		qcom,msm-bus,vectors-KBps =
			<63 512 0 0>,
			<63 512 0 304000>;
		qcom,proxy-timeout-ms = <100>;
		qcom,firmware-name = "venus";
		memory-region = <&pil_video_mem>;
	};

	kryo-erp {
		compatible = "arm,arm64-kryo-cpu-erp";
		interrupts = <1 6 4>,
			     <1 7 4>,
			     <0 34 4>,
			     <0 35 4>;

		interrupt-names = "l1-l2-faultirq",
				  "l1-l2-errirq",
				  "l3-scu-errirq",
				  "l3-scu-faultirq";
	};

	qcom,chd_sliver {
		compatible = "qcom,core-hang-detect";
		label = "silver";
		qcom,threshold-arr = <0x18000058 0x18010058
		0x18020058 0x18030058>;
		qcom,config-arr = <0x18000060 0x18010060
		0x18020060 0x18030060>;
	};

	qcom,chd_gold {
		compatible = "qcom,core-hang-detect";
		label = "gold";
		qcom,threshold-arr = <0x18040058 0x18050058
		0x18060058 0x18070058>;
		qcom,config-arr = <0x18040060 0x18050060
		0x18060060 0x18070060>;
	};

	qcom,ghd {
		compatible = "qcom,gladiator-hang-detect-v3";
		qcom,threshold-arr = <0x17e0041C>;
		qcom,config-reg = <0x17e00434>;
	};

	qcom,llcc@9200000 {
		compatible = "qcom,llcc-core", "syscon", "simple-mfd";
		reg = <0x9200000 0x450000>;
		reg-names = "llcc_base";
		qcom,llcc-banks-off = <0x0 0x80000 0x100000 0x180000>;
		qcom,llcc-broadcast-off = <0x400000>;

		llcc: qcom,sdm855-llcc {
			compatible = "qcom,sdm855-llcc";
			#cache-cells = <1>;
			max-slices = <32>;
		};

		qcom,llcc-erp {
			compatible = "qcom,llcc-erp";
			interrupt-names = "ecc_irq";
			interrupts = <GIC_SPI 582 IRQ_TYPE_LEVEL_HIGH>;
		};

		qcom,llcc-amon {
			compatible = "qcom,llcc-amon";
		};
	};

	ssc_sensors: qcom,msm-ssc-sensors {
		compatible = "qcom,msm-ssc-sensors";
		status = "ok";
		qcom,firmware-name = "slpi";
	};

	cpuss_dump {
		compatible = "qcom,cpuss-dump";

		qcom,l1_i_cache0 {
			qcom,dump-node = <&L1_I_0>;
			qcom,dump-id = <0x60>;
		};

		qcom,l1_i_cache1 {
			qcom,dump-node = <&L1_I_100>;
			qcom,dump-id = <0x61>;
		};

		qcom,l1_i_cache2 {
			qcom,dump-node = <&L1_I_200>;
			qcom,dump-id = <0x62>;
		};

		qcom,l1_i_cache3 {
			qcom,dump-node = <&L1_I_300>;
			qcom,dump-id = <0x63>;
		};

		qcom,l1_i_cache100 {
			qcom,dump-node = <&L1_I_400>;
			qcom,dump-id = <0x64>;
		};

		qcom,l1_i_cache101 {
			qcom,dump-node = <&L1_I_500>;
			qcom,dump-id = <0x65>;
		};

		qcom,l1_i_cache102 {
			qcom,dump-node = <&L1_I_600>;
			qcom,dump-id = <0x66>;
		};

		qcom,l1_i_cache103 {
			qcom,dump-node = <&L1_I_700>;
			qcom,dump-id = <0x67>;
		};

		qcom,l1_d_cache0 {
			qcom,dump-node = <&L1_D_0>;
			qcom,dump-id = <0x80>;
		};

		qcom,l1_d_cache1 {
			qcom,dump-node = <&L1_D_100>;
			qcom,dump-id = <0x81>;
		};

		qcom,l1_d_cache2 {
			qcom,dump-node = <&L1_D_200>;
			qcom,dump-id = <0x82>;
		};

		qcom,l1_d_cache3 {
			qcom,dump-node = <&L1_D_300>;
			qcom,dump-id = <0x83>;
		};

		qcom,l1_d_cache100 {
			qcom,dump-node = <&L1_D_400>;
			qcom,dump-id = <0x84>;
		};

		qcom,l1_d_cache101 {
			qcom,dump-node = <&L1_D_500>;
			qcom,dump-id = <0x85>;
		};

		qcom,l1_d_cache102 {
			qcom,dump-node = <&L1_D_600>;
			qcom,dump-id = <0x86>;
		};

		qcom,l1_d_cache103 {
			qcom,dump-node = <&L1_D_700>;
			qcom,dump-id = <0x87>;
		};

		qcom,l1_tlb_dump0 {
			qcom,dump-node = <&L1_TLB_0>;
			qcom,dump-id = <0x20>;
		};

		qcom,l1_tlb_dump100 {
			qcom,dump-node = <&L1_TLB_100>;
			qcom,dump-id = <0x21>;
		};

		qcom,l1_tlb_dump200 {
			qcom,dump-node = <&L1_TLB_200>;
			qcom,dump-id = <0x22>;
		};

		qcom,l1_tlb_dump300 {
			qcom,dump-node = <&L1_TLB_300>;
			qcom,dump-id = <0x23>;
		};

		qcom,l1_tlb_dump400 {
			qcom,dump-node = <&L1_TLB_400>;
			qcom,dump-id = <0x24>;
		};

		qcom,l1_tlb_dump500 {
			qcom,dump-node = <&L1_TLB_500>;
			qcom,dump-id = <0x25>;
		};

		qcom,l1_tlb_dump600 {
			qcom,dump-node = <&L1_TLB_600>;
			qcom,dump-id = <0x26>;
		};

		qcom,l1_tlb_dump700 {
			qcom,dump-node = <&L1_TLB_700>;
			qcom,dump-id = <0x27>;
		};
	};

	qcom,sps {
		compatible = "qcom,msm_sps_4k";
		qcom,pipe-attr-ee;
	};

	usb0: ssusb@a600000 {
		compatible = "qcom,dwc3";
		reg = <0x0a600000 0x100000>;
		reg-names = "base";
		#address-cells = <1>;
		#size-cells = <1>;
		ranges;

		USB3_GDSC-supply = <&usb30_prim_gdsc>;

		clocks = <&clock_gcc GCC_USB30_PRIM_MASTER_CLK>,
			 <&clock_gcc GCC_CFG_NOC_USB3_PRIM_AXI_CLK>,
			 <&clock_gcc GCC_AGGRE_USB3_PRIM_AXI_CLK>,
			 <&clock_gcc GCC_USB30_PRIM_MOCK_UTMI_CLK>,
			 <&clock_gcc GCC_USB30_PRIM_SLEEP_CLK>,
			 <&clock_gcc GCC_USB3_PRIM_CLKREF_CLK>;

		clock-names = "core_clk", "iface_clk", "bus_aggr_clk",
			"utmi_clk", "sleep_clk", "xo";

		dwc3@a600000 {
			compatible = "snps,dwc3";
			reg = <0x0a600000 0xcd00>;
			interrupt-parent = <&intc>;
			interrupts = <0 133 0>;
			tx-fifo-resize;
			linux,sysdev_is_parent;
			snps,disable-clk-gating;
			snps,has-lpm-erratum;
			snps,hird-threshold = /bits/ 8 <0x10>;
		};
	};

	tcsr_mutex_block: syscon@1f40000 {
		compatible = "syscon";
		reg = <0x1f40000 0x20000>;
	};

	tcsr_mutex: hwlock@1f40000 {
		compatible = "qcom,tcsr-mutex";
		syscon = <&tcsr_mutex_block 0 0x1000>;
		#hwlock-cells = <1>;
	};

	smem: qcom,smem@8600000 {
		compatible = "qcom,smem";
		memory-region = <&smem_region>;
		hwlocks = <&tcsr_mutex 3>;
	};

	apcs: syscon@17c0000c {
		compatible = "syscon";
		reg = <0x17c0000c 0x4>;
	};

	ufsphy_mem: ufsphy_mem@1d87000 {
		reg = <0x1d87000 0xda8>; /* PHY regs */
		reg-names = "phy_mem";
		#phy-cells = <0>;

		lanes-per-direction = <2>;

		clock-names = "ref_clk_src",
			"ref_clk",
			"ref_aux_clk";
		clocks = <&clock_rpmh RPMH_CXO_CLK>,
			<&clock_gcc GCC_UFS_MEM_CLKREF_CLK>,
			<&clock_gcc GCC_UFS_PHY_PHY_AUX_CLK>;

		status = "disabled";
	};

	ufshc_mem: ufshc@1d84000 {
		compatible = "qcom,ufshc";
		reg = <0x1d84000 0x2500>;
		interrupts = <0 265 0>;
		phys = <&ufsphy_mem>;
		phy-names = "ufsphy";

		lanes-per-direction = <2>;
		dev-ref-clk-freq = <0>; /* 19.2 MHz */

		clock-names =
			"core_clk",
			"bus_aggr_clk",
			"iface_clk",
			"core_clk_unipro",
			"core_clk_ice",
			"ref_clk",
			"tx_lane0_sync_clk",
			"rx_lane0_sync_clk",
			"rx_lane1_sync_clk";
		clocks =
			<&clock_gcc GCC_UFS_PHY_AXI_CLK>,
			<&clock_gcc GCC_AGGRE_UFS_PHY_AXI_CLK>,
			<&clock_gcc GCC_UFS_PHY_AHB_CLK>,
			<&clock_gcc GCC_UFS_PHY_UNIPRO_CORE_CLK>,
			<&clock_gcc GCC_UFS_PHY_ICE_CORE_CLK>,
			<&clock_rpmh RPMH_CXO_CLK>,
			<&clock_gcc GCC_UFS_PHY_TX_SYMBOL_0_CLK>,
			<&clock_gcc GCC_UFS_PHY_RX_SYMBOL_0_CLK>,
			<&clock_gcc GCC_UFS_PHY_RX_SYMBOL_1_CLK>;
		freq-table-hz =
			<50000000 200000000>,
			<0 0>,
			<0 0>,
			<37500000 150000000>,
			<75000000 300000000>,
			<0 0>,
			<0 0>,
			<0 0>,
			<0 0>;

		qcom,msm-bus,name = "ufshc_mem";
		qcom,msm-bus,num-cases = <22>;
		qcom,msm-bus,num-paths = <2>;
		qcom,msm-bus,vectors-KBps =
		/*
		 * During HS G3 UFS runs at nominal voltage corner, vote
		 * higher bandwidth to push other buses in the data path
		 * to run at nominal to achieve max throughput.
		 * 4GBps pushes BIMC to run at nominal.
		 * 200MBps pushes CNOC to run at nominal.
		 * Vote for half of this bandwidth for HS G3 1-lane.
		 * For max bandwidth, vote high enough to push the buses
		 * to run in turbo voltage corner.
		 */
		<123 512 0 0>, <1 757 0 0>,          /* No vote */
		<123 512 922 0>, <1 757 1000 0>,     /* PWM G1 */
		<123 512 1844 0>, <1 757 1000 0>,    /* PWM G2 */
		<123 512 3688 0>, <1 757 1000 0>,    /* PWM G3 */
		<123 512 7376 0>, <1 757 1000 0>,    /* PWM G4 */
		<123 512 1844 0>, <1 757 1000 0>,    /* PWM G1 L2 */
		<123 512 3688 0>, <1 757 1000 0>,    /* PWM G2 L2 */
		<123 512 7376 0>, <1 757 1000 0>,    /* PWM G3 L2 */
		<123 512 14752 0>, <1 757 1000 0>,   /* PWM G4 L2 */
		<123 512 127796 0>, <1 757 1000 0>,  /* HS G1 RA */
		<123 512 255591 0>, <1 757 1000 0>,  /* HS G2 RA */
		<123 512 2097152 0>, <1 757 102400 0>,  /* HS G3 RA */
		<123 512 255591 0>, <1 757 1000 0>,  /* HS G1 RA L2 */
		<123 512 511181 0>, <1 757 1000 0>,  /* HS G2 RA L2 */
		<123 512 4194304 0>, <1 757 204800 0>, /* HS G3 RA L2 */
		<123 512 149422 0>, <1 757 1000 0>,  /* HS G1 RB */
		<123 512 298189 0>, <1 757 1000 0>,  /* HS G2 RB */
		<123 512 2097152 0>, <1 757 102400 0>,  /* HS G3 RB */
		<123 512 298189 0>, <1 757 1000 0>,  /* HS G1 RB L2 */
		<123 512 596378 0>, <1 757 1000 0>,  /* HS G2 RB L2 */
		<123 512 4194304 0>, <1 757 204800 0>, /* HS G3 RB L2 */
		<123 512 7643136 0>, <1 757 307200 0>; /* Max. bandwidth */

		qcom,bus-vector-names = "MIN",
		"PWM_G1_L1", "PWM_G2_L1", "PWM_G3_L1", "PWM_G4_L1",
		"PWM_G1_L2", "PWM_G2_L2", "PWM_G3_L2", "PWM_G4_L2",
		"HS_RA_G1_L1", "HS_RA_G2_L1", "HS_RA_G3_L1",
		"HS_RA_G1_L2", "HS_RA_G2_L2", "HS_RA_G3_L2",
		"HS_RB_G1_L1", "HS_RB_G2_L1", "HS_RB_G3_L1",
		"HS_RB_G1_L2", "HS_RB_G2_L2", "HS_RB_G3_L2",
		"MAX";

		/* PM QoS */
		qcom,pm-qos-cpu-groups = <0x0f 0xf0>;
		qcom,pm-qos-cpu-group-latency-us = <70 70>;
		qcom,pm-qos-default-cpu = <0>;

		pinctrl-names = "dev-reset-assert", "dev-reset-deassert";
		pinctrl-0 = <&ufs_dev_reset_assert>;
		pinctrl-1 = <&ufs_dev_reset_deassert>;

		resets = <&clock_gcc GCC_UFS_PHY_BCR>;
		reset-names = "core_reset";

		status = "disabled";
	};

	extcon_storage_cd: extcon_storage_cd {
		compatible = "extcon-gpio";
		extcon-id = <62>; /* EXTCON_MECHANICAL */
		status = "disabled";
	};

	ufsphy_card: ufsphy_card@1da7000 {
		reg = <0x1da7000 0xda8>; /* PHY regs */
		reg-names = "phy_mem";
		#phy-cells = <0>;

		lanes-per-direction = <1>;

		status = "disabled";
	};

	ufshc_card: ufshc_card@1da4000 {
		compatible = "qcom,ufshc";
		reg = <0x1da4000 0x2500>;
		interrupts = <0 125 0>;
		phys = <&ufsphy_card>;
		phy-names = "ufsphy";

		lanes-per-direction = <1>;
		dev-ref-clk-freq = <0>; /* 19.2 MHz */

		clock-names =
			"tx_lane0_sync_clk",
			"rx_lane0_sync_clk";
		clocks =
			<&clock_gcc GCC_UFS_CARD_TX_SYMBOL_0_CLK>,
			<&clock_gcc GCC_UFS_CARD_RX_SYMBOL_0_CLK>;
		freq-table-hz =
			<0 0>,
			<0 0>;

		qcom,msm-bus,name = "ufshc_card";
		qcom,msm-bus,num-cases = <9>;
		qcom,msm-bus,num-paths = <2>;
		qcom,msm-bus,vectors-KBps =
		<122 512 0 0>, <1 756 0 0>,          /* No vote */
		<122 512 922 0>, <1 756 1000 0>,     /* PWM G1 */
		<122 512 127796 0>, <1 756 1000 0>,  /* HS G1 RA */
		<122 512 255591 0>, <1 756 1000 0>,  /* HS G2 RA */
		<122 512 2097152 0>, <1 756 102400 0>,  /* HS G3 RA */
		<122 512 149422 0>, <1 756 1000 0>,  /* HS G1 RB */
		<122 512 298189 0>, <1 756 1000 0>,  /* HS G2 RB */
		<122 512 2097152 0>, <1 756 102400 0>,  /* HS G3 RB */
		<122 512 7643136 0>, <1 756 307200 0>; /* Max. bandwidth */
		qcom,bus-vector-names = "MIN",
		"PWM_G1_L1",
		"HS_RA_G1_L1", "HS_RA_G2_L1", "HS_RA_G3_L1",
		"HS_RB_G1_L1", "HS_RB_G2_L1", "HS_RB_G3_L1",
		"MAX";

		/* PM QoS */
		qcom,pm-qos-cpu-groups = <0x0f 0xf0>;
		qcom,pm-qos-cpu-group-latency-us = <70 70>;
		qcom,pm-qos-default-cpu = <0>;

		/*
		 * Note: this instance doesn't have control over UFS device
		 * reset
		 */

		resets = <&clock_gcc GCC_UFS_CARD_BCR>;
		reset-names = "core_reset";

		status = "disabled";
	};

	apps_rsc: mailbox@18220000 {
		compatible = "qcom,tcs-drv";
		label = "apps_rsc";
		reg = <0x18220000 0x100>, <0x18220d00 0x3000>;
		interrupts = <0 5 0>;
		#mbox-cells = <1>;
		qcom,drv-id = <2>;
		qcom,tcs-config = <ACTIVE_TCS  2>,
				  <SLEEP_TCS   3>,
				  <WAKE_TCS    3>,
				  <CONTROL_TCS 1>;
	};

	disp_rsc: mailbox@af20000 {
		compatible = "qcom,tcs-drv";
		label = "display_rsc";
		reg = <0xaf20000 0x100>, <0xaf21c00 0x3000>;
		interrupts = <0 129 0>;
		#mbox-cells = <1>;
		qcom,drv-id = <0>;
		qcom,tcs-config = <ACTIVE_TCS  2>,
				  <SLEEP_TCS   1>,
				  <WAKE_TCS    1>,
				  <CONTROL_TCS 0>;
	};

	apcs_glb: mailbox@17c00000 {
		compatible = "qcom,sdm855-apcs-hmss-global";
		reg = <0x17c00000 0x1000>;

		#mbox-cells = <1>;
	};

	qcom,glink {
		compatible = "qcom,glink";
		modem {
			qcom,remote-pid = <1>;
			transport = "smem";
			mboxes = <&apcs_glb 12>;
			mbox-names = "mpss_smem";
			interrupts = <GIC_SPI 449 IRQ_TYPE_EDGE_RISING>;
		};

		adsp {
			qcom,remote-pid = <2>;
			transport = "smem";
			mboxes = <&apcs_glb 8>;
			mbox-names = "adsp_smem";
			interrupts = <GIC_SPI 156 IRQ_TYPE_EDGE_RISING>;
		};

		dsps {
			qcom,remote-pid = <3>;
			transport = "smem";
			mboxes = <&apcs_glb 24>;
			mbox-names = "dsps_smem";
			interrupts = <GIC_SPI 170 IRQ_TYPE_EDGE_RISING>;
		};

		cdsp {
			qcom,remote-pid = <5>;
			transport = "smem";
			mboxes = <&apcs_glb 4>;
			mbox-names = "cdsp_smem";
			interrupts = <GIC_SPI 574 IRQ_TYPE_EDGE_RISING>;
		};
	};

	qmp_aop: qcom,qmp-aop@c300000 {
		compatible = "qcom,qmp-mbox";
		reg = <0xc300000 0x1000>, <0x17c0000C 0x4>;
		reg-names = "msgram", "irq-reg-base";
		qcom,irq-mask = <0x1>;
		interrupts = <GIC_SPI 389 IRQ_TYPE_EDGE_RISING>;

		label = "aop";
		priority = <0>;
		mbox-desc-offset = <0x0>;
		#mbox-cells = <1>;
	};

	qmp_npu0: qcom,qmp-npu-low@9818000 {
		compatible = "qcom,qmp-mbox";
		reg = <0x9818000 0x8000>, <0x17c00010 0x4>;
		reg-names = "msgram", "irq-reg-base";
		qcom,irq-mask = <0x20>;
		interrupts = <GIC_SPI 369 IRQ_TYPE_EDGE_RISING>;

		label = "npu_qmp_low";
		priority = <0>;
		mbox-desc-offset = <0x0>;
		#mbox-cells = <1>;
	};

	qmp_npu1: qcom,qmp-npu-high@9818200 {
		compatible = "qcom,qmp-mbox";
		reg = <0x9818000 0x8000>, <0x17c00010 0x4>;
		reg-names = "msgram", "irq-reg-base";
		qcom,irq-mask = <0x40>;
		interrupts = <GIC_SPI 370 IRQ_TYPE_EDGE_RISING>;

		label = "npu_qmp_high";
		priority = <1>;
		mbox-desc-offset = <0x200>;
		#mbox-cells = <1>;
	};

	system_pm {
		compatible = "qcom,system-pm";
		mboxes = <&apps_rsc 0>;
	};

	cmd_db: qcom,cmd-db@c3f000c {
		compatible = "qcom,cmd-db";
		reg = <0xc3f000c 8>;
	};

	mem_dump {
		compatible = "qcom,mem-dump";
		memory-region = <&dump_mem>;

		rpmh_dump {
			qcom,dump-size = <0x2000000>;
			qcom,dump-id = <0xec>;
		};

		rpm_sw_dump {
			qcom,dump-size = <0x28000>;
			qcom,dump-id = <0xea>;
		};

		pmic_dump {
			qcom,dump-size = <0x10000>;
			qcom,dump-id = <0xe4>;
		};

		tmc_etf_dump {
			qcom,dump-size = <0x10000>;
			qcom,dump-id = <0xf0>;
		};

		tmc_etf_swao_dump {
			qcom,dump-size = <0x8400>;
			qcom,dump-id = <0xf1>;
		};

		tmc_etr_reg_dump {
			qcom,dump-size = <0x1000>;
			qcom,dump-id = <0x100>;
		};

		tmc_etf_reg_dump {
			qcom,dump-size = <0x1000>;
			qcom,dump-id = <0x101>;
		};

		tmc_etf_swao_reg_dump {
			qcom,dump-size = <0x1000>;
			qcom,dump-id = <0x102>;
		};

		misc_data_dump {
			qcom,dump-size = <0x1000>;
			qcom,dump-id = <0xe8>;
		};
	};

	dcc: dcc_v2@10a2000 {
		compatible = "qcom,dcc_v2";
		reg = <0x10a2000 0x1000>,
		      <0x10ae000 0x2000>;
		reg-names = "dcc-base", "dcc-ram-base";

		dcc-ram-offset = <0x6000>;

		qcom,curr-link-list = <2>;
		qcom,link-list = <DCC_READ 0x1740300 6 0>,
				 <DCC_READ 0x1620500 4 0>,
				 <DCC_READ 0x7840000 1 0>,
				 <DCC_READ 0x7841010 12 0>,
				 <DCC_READ 0x7842000 16 0>,
				 <DCC_READ 0x7842500 2 0>,
				 <DCC_LOOP 7 0 0>,
				 <DCC_READ 0x7841000 1 0>,
				 <DCC_LOOP 1 0 0>,
				 <DCC_LOOP 165 0 0>,
				 <DCC_READ 0x7841008 2 0>,
				 <DCC_LOOP 1 0 0>,
				 <DCC_READ 0x17dc3a84 2 0>,
				 <DCC_READ 0x17db3a84 1 0>,
				 <DCC_READ 0x1301000 2 0>,
				 <DCC_READ 0x17990044 1 0>,
				 <DCC_READ 0x17d45f00 1 0>,
				 <DCC_READ 0x17d45f08 6 0>,
				 <DCC_READ 0x17d45f80 1 0>,
				 <DCC_READ 0x17d47418 1 0>,
				 <DCC_READ 0x17d47570 1 0>,
				 <DCC_READ 0x17d47588 1 0>,
				 <DCC_READ 0x17d43700 1 0>,
				 <DCC_READ 0x17d43708 6 0>,
				 <DCC_READ 0x17d43780 1 0>,
				 <DCC_READ 0x17d44c18 1 0>,
				 <DCC_READ 0x17d44d70 1 0>,
				 <DCC_READ 0x17d44d88 1 0>,
				 <DCC_READ 0x17d41700 1 0>,
				 <DCC_READ 0x17d41708 6 0>,
				 <DCC_READ 0x17d41780 1 0>,
				 <DCC_READ 0x17d42c18 1 0>,
				 <DCC_READ 0x17d42d70 1 0>,
				 <DCC_READ 0x17d42d88 1 0>,
				 <DCC_WRITE 0x69ea00c 0x600007 1>,
				 <DCC_WRITE 0x69ea01c 0x136800 1>,
				 <DCC_READ 0x69ea014 1 1>,
				 <DCC_WRITE 0x69ea01c 0x136810 1>,
				 <DCC_READ 0x69ea014 1 1>,
				 <DCC_WRITE 0x69ea01c 0x136820 1>,
				 <DCC_READ 0x69ea014 1 1>,
				 <DCC_WRITE 0x69ea01c 0x136830 1>,
				 <DCC_READ 0x69ea014 1 1>,
				 <DCC_WRITE 0x69ea01c 0x136840 1>,
				 <DCC_READ 0x69ea014 1 1>,
				 <DCC_WRITE 0x69ea01c 0x136850 1>,
				 <DCC_READ 0x69ea014 1 1>,
				 <DCC_WRITE 0x69ea01c 0x136860 1>,
				 <DCC_READ 0x69ea014 1 1>,
				 <DCC_WRITE 0x69ea01c 0x136870 1>,
				 <DCC_READ 0x69ea014 1 1>,
				 <DCC_WRITE 0x069ea01C 0x0003e9a0 1>,
				 <DCC_WRITE 0x069ea01C 0x001368a0 1>,
				 <DCC_READ 0x069ea014 1 1>,
				 <DCC_WRITE 0x069ea01c 0x0003c0a0 1>,
				 <DCC_WRITE 0x069ea01c 0x001368a0 1>,
				 <DCC_READ 0x069ea014 1 1>,
				 <DCC_WRITE 0x069ea01c 0x0003d1a0 1>,
				 <DCC_WRITE 0x069ea01C 0x001368a0 1>,
				 <DCC_READ 0x069ea014 1 1>,
				 <DCC_WRITE 0x069ea01c 0x0003d2a0 1>,
				 <DCC_WRITE 0x069ea01c 0x001368a0 1>,
				 <DCC_READ 0x069ea014 1 1>,
				 <DCC_WRITE 0x069ea01C 0x0003d5a0 1>,
				 <DCC_WRITE 0x069ea01C 0x001368a0 1>,
				 <DCC_READ 0x069ea014 1 1>,
				 <DCC_WRITE 0x069ea01C 0x0003d6a0 1>,
				 <DCC_WRITE 0x069ea01C 0x001368a0 1>,
				 <DCC_READ 0x069ea014 1 1>,
				 <DCC_WRITE 0x069ea01c 0x001368a0 1>,
				 <DCC_WRITE 0x069ea01c 0x001368a0 1>,
				 <DCC_READ 0x069ea014 1 1>,
				 <DCC_WRITE 0x069ea01c 0x0003b1a0 1>,
				 <DCC_WRITE 0x069ea01c 0x001368a0 1>,
				 <DCC_READ 0x069ea014 1 1>,
				 <DCC_WRITE 0x069ea01c 0x0003b2a0 1>,
				 <DCC_WRITE 0x069ea01c 0x001368a0 1>,
				 <DCC_READ 0x069ea014 1 1>,
				 <DCC_WRITE 0x069ea01c 0x0003b5a0 1>,
				 <DCC_WRITE 0x069ea01c 0x001368a0 1>,
				 <DCC_READ 0x069ea014 1 1>,
				 <DCC_WRITE 0x069ea01c 0x0003b6a0 1>,
				 <DCC_WRITE 0x069ea01c 0x001368a0 1>,
				 <DCC_READ 0x069ea014 1 1>,
				 <DCC_WRITE 0x069ea01c 0x0003c2a0 1>,
				 <DCC_WRITE 0x069ea01c 0x001368a0 1>,
				 <DCC_READ 0x069ea014 1 1>,
				 <DCC_WRITE 0x069ea01c 0x0003c5a0 1>,
				 <DCC_WRITE 0x069ea01c 0x001368a0 1>,
				 <DCC_READ 0x069ea014 1 1>,
				 <DCC_WRITE 0x069ea01c 0x0003c6a0 1>,
				 <DCC_WRITE 0x069ea01c 0x001368a0 1>,
				 <DCC_READ 0x069ea014 1 1>,
				 <DCC_WRITE 0x069ea01c 0x00f1e000 1>,
				 <DCC_WRITE 0x069ea008 0x00000007 1>,
				 <DCC_READ 0x013e7e00 31 0>,
				 <DCC_READ 0x01132100 1 0>,
				 <DCC_READ 0x01136044 4 0>,
				 <DCC_READ 0x011360b0 1 0>,
				 <DCC_READ 0x0113e030 2 0>,
				 <DCC_READ 0x01141000 1 0>,
				 <DCC_READ 0x01142028 1 0>,
				 <DCC_READ 0x01148058 4 0>,
				 <DCC_READ 0x01160410 3 0>,
				 <DCC_READ 0x011604a0 1 0>,
				 <DCC_READ 0x011604b8 1 0>,
				 <DCC_READ 0x01165804 1 0>,
				 <DCC_READ 0x01166418 1 0>,
				 <DCC_READ 0x011b2100 1 0>,
				 <DCC_READ 0x011b6044 4 0>,
				 <DCC_READ 0x011be030 2 0>,
				 <DCC_READ 0x011c1000 1 0>,
				 <DCC_READ 0x011c2028 1 0>,
				 <DCC_READ 0x011c8058 4 0>,
				 <DCC_READ 0x011e0410 3 0>,
				 <DCC_READ 0x011e04a0 1 0>,
				 <DCC_READ 0x011e04b8 1 0>,
				 <DCC_READ 0x011e5804 1 0>,
				 <DCC_READ 0x011e6418 1 0>,
				 <DCC_READ 0x01232100 1 0>,
				 <DCC_READ 0x01236044 4 0>,
				 <DCC_READ 0x012360B0 1 0>,
				 <DCC_READ 0x0123E030 2 0>,
				 <DCC_READ 0x01241000 1 0>,
				 <DCC_READ 0x01242028 1 0>,
				 <DCC_READ 0x01248058 4 0>,
				 <DCC_READ 0x01260410 3 0>,
				 <DCC_READ 0x012604a0 1 0>,
				 <DCC_READ 0x012604b8 1 0>,
				 <DCC_READ 0x01265804 1 0>,
				 <DCC_READ 0x01266418 1 0>,
				 <DCC_READ 0x012b2100 1 0>,
				 <DCC_READ 0x012b6044 3 0>,
				 <DCC_READ 0x012b6050 1 0>,
				 <DCC_READ 0x012b60b0 1 0>,
				 <DCC_READ 0x012be030 2 0>,
				 <DCC_READ 0x012c1000 1 0>,
				 <DCC_READ 0x012c2028 1 0>,
				 <DCC_READ 0x012c8058 4 0>,
				 <DCC_READ 0x012e0410 3 0>,
				 <DCC_READ 0x012e04a0 1 0>,
				 <DCC_READ 0x012e04b8 1 0>,
				 <DCC_READ 0x012e5804 1 0>,
				 <DCC_READ 0x012e6418 1 0>,
				 <DCC_READ 0x01380900 8 0>,
				 <DCC_READ 0x01380d00 5 0>,
				 <DCC_READ 0x01350110 4 0>,
				 <DCC_READ 0x01430280 1 0>,
				 <DCC_READ 0x01430288 1 0>,
				 <DCC_READ 0x0143028c 7 0>,
				 <DCC_READ 0x01132100 1 0>,
				 <DCC_READ 0x01136044 4 0>,
				 <DCC_READ 0x011360b0 1 0>,
				 <DCC_READ 0x0113e030 2 0>,
				 <DCC_READ 0x01141000 1 0>,
				 <DCC_READ 0x01142028 1 0>,
				 <DCC_READ 0x01148058 4 0>,
				 <DCC_READ 0x01160410 3 0>,
				 <DCC_READ 0x011604a0 1 0>,
				 <DCC_READ 0x011604b8 1 0>,
				 <DCC_READ 0x01165804 1 0>,
				 <DCC_READ 0x01166418 1 0>,
				 <DCC_READ 0x011b2100 1 0>,
				 <DCC_READ 0x011b6044 4 0>,
				 <DCC_READ 0x011be030 2 0>,
				 <DCC_READ 0x011c1000 1 0>,
				 <DCC_READ 0x011c2028 1 0>,
				 <DCC_READ 0x011c8058 4 0>,
				 <DCC_READ 0x011e0410 3 0>,
				 <DCC_READ 0x011e04a0 1 0>,
				 <DCC_READ 0x011e04b8 1 0>,
				 <DCC_READ 0x011e5804 1 0>,
				 <DCC_READ 0x011e6418 1 0>,
				 <DCC_READ 0x01232100 1 0>,
				 <DCC_READ 0x01236044 4 0>,
				 <DCC_READ 0x012360b0 1 0>,
				 <DCC_READ 0x0123e030 2 0>,
				 <DCC_READ 0x01241000 1 0>,
				 <DCC_READ 0x01242028 1 0>,
				 <DCC_READ 0x01248058 4 0>,
				 <DCC_READ 0x01260410 3 0>,
				 <DCC_READ 0x012604a0 1 0>,
				 <DCC_READ 0x012604b8 1 0>,
				 <DCC_READ 0x01265804 1 0>,
				 <DCC_READ 0x01266418 1 0>,
				 <DCC_READ 0x012b2100 1 0>,
				 <DCC_READ 0x012b6044 3 0>,
				 <DCC_READ 0x012b6050 1 0>,
				 <DCC_READ 0x012b60b0 1 0>,
				 <DCC_READ 0x012be030 2 0>,
				 <DCC_READ 0x012C1000 1 0>,
				 <DCC_READ 0x012C2028 1 0>,
				 <DCC_READ 0x012C8058 4 0>,
				 <DCC_READ 0x012e0410 3 0>,
				 <DCC_READ 0x012e04a0 1 0>,
				 <DCC_READ 0x012e04b8 1 0>,
				 <DCC_READ 0x012e5804 1 0>,
				 <DCC_READ 0x012e6418 1 0>,
				 <DCC_READ 0x01380900 8 0>,
				 <DCC_READ 0x01380d00 5 0>,
				 <DCC_READ 0x01350110 4 0>,
				 <DCC_READ 0x01430280 1 0>,
				 <DCC_READ 0x01430288 1 0>,
				 <DCC_READ 0x0143028c 7 0>,
				 <DCC_READ 0x0c201244 1 0>,
				 <DCC_READ 0x0c202244 1 0>;
	};

	tsens0: tsens@c222000 {
		compatible = "qcom,tsens24xx";
		reg = <0xc222000 0x4>,
			<0xc263000 0x1ff>;
		reg-names = "tsens_srot_physical",
				"tsens_tm_physical";
		interrupts = <0 506 0>, <0 508 0>;
		interrupt-names = "tsens-upper-lower", "tsens-critical";
		#thermal-sensor-cells = <1>;
	};

	tsens1: tsens@c223000 {
		compatible = "qcom,tsens24xx";
		reg = <0xc223000 0x4>,
			<0xc265000 0x1ff>;
		reg-names = "tsens_srot_physical",
			"tsens_tm_physical";
		interrupts = <0 507 0>, <0 509 0>;
		interrupt-names = "tsens-upper-lower", "tsens-critical";
		#thermal-sensor-cells = <1>;
	};

	thermal_zones: thermal-zones {
	};

	slim_aud: slim@171c0000 {
		cell-index = <1>;
		compatible = "qcom,slim-ngd";
		reg = <0x171c0000 0x2c000>,
			<0x17184000 0x2c000>;
		reg-names = "slimbus_physical", "slimbus_bam_physical";
		interrupts = <0 163 0>, <0 164 0>;
		interrupt-names = "slimbus_irq", "slimbus_bam_irq";
		qcom,apps-ch-pipes = <0x780000>;
		qcom,ea-pc = <0x2a0>;
		qcom,iommu-s1-bypass;

		iommu_slim_aud_ctrl_cb: qcom,iommu_slim_ctrl_cb {
			compatible = "qcom,iommu-slim-ctrl-cb";
			iommus = <&apps_smmu 0x1b46 0x8>,
				 <&apps_smmu 0x1b4d 0x2>,
				 <&apps_smmu 0x1b50 0x1>;
		};
	};

	slim_qca: slim@17240000 {
		cell-index = <3>;
		compatible = "qcom,slim-ngd";
		reg = <0x17240000 0x2c000>,
			<0x17204000 0x20000>;
		reg-names = "slimbus_physical", "slimbus_bam_physical";
		interrupts = <0 291 0>, <0 292 0>;
		interrupt-names = "slimbus_irq", "slimbus_bam_irq";
	};
};

&emac_gdsc {
	status = "ok";
};

&pcie_0_gdsc {
	status = "ok";
};

&pcie_1_gdsc {
	status = "ok";
};

&ufs_card_gdsc {
	status = "ok";
};

&ufs_phy_gdsc {
	status = "ok";
};

&usb30_prim_gdsc {
	status = "ok";
};

&usb30_sec_gdsc {
	status = "ok";
};

&hlos1_vote_aggre_noc_mmu_audio_tbu_gdsc {
	status = "ok";
};

&hlos1_vote_aggre_noc_mmu_tbu1_gdsc {
	status = "ok";
};

&hlos1_vote_aggre_noc_mmu_tbu2_gdsc {
	status = "ok";
};

&hlos1_vote_aggre_noc_mmu_pcie_tbu_gdsc {
	status = "ok";
};

&hlos1_vote_mmnoc_mmu_tbu_hf0_gdsc {
	status = "ok";
};

&hlos1_vote_mmnoc_mmu_tbu_sf_gdsc {
	status = "ok";
};

&hlos1_vote_mmnoc_mmu_tbu_hf1_gdsc {
	status = "ok";
};

&hlos1_vote_turing_mmu_tbu0_gdsc {
	status = "ok";
};

&hlos1_vote_turing_mmu_tbu1_gdsc {
	status = "ok";
};

&bps_gdsc {
	parent-supply = <&pm855l_s5_level>;
	qcom,vote-parent-supply-voltage;
	status = "ok";
};

&ipe_0_gdsc {
	parent-supply = <&pm855l_s5_level>;
	qcom,vote-parent-supply-voltage;
	status = "ok";
};

&ipe_1_gdsc {
	parent-supply = <&pm855l_s5_level>;
	qcom,vote-parent-supply-voltage;
	status = "ok";
};

&ife_0_gdsc {
	parent-supply = <&pm855l_s5_level>;
	qcom,vote-parent-supply-voltage;
	status = "ok";
};

&ife_1_gdsc {
	parent-supply = <&pm855l_s5_level>;
	qcom,vote-parent-supply-voltage;
	status = "ok";
};

&titan_top_gdsc {
	parent-supply = <&pm855l_s5_level>;
	qcom,vote-parent-supply-voltage;
	status = "ok";
};

&mdss_core_gdsc {
	parent-supply = <&pm855l_s5_level>;
	qcom,vote-parent-supply-voltage;
	status = "ok";
};

&gpu_cx_gdsc {
	status = "ok";
};

&gpu_gx_gdsc {
	parent-supply = <&pm855l_s2_level>;
	qcom,vote-parent-supply-voltage;
	clock-names = "core_root_clk";
	clocks = <&clock_gpucc GPU_CC_GX_GFX3D_CLK_SRC>;
	qcom,force-enable-root-clk;
	status = "ok";
};

&mvsc_gdsc {
	parent-supply = <&pm855l_s5_level>;
	qcom,vote-parent-supply-voltage;
	status = "ok";
};

&mvs0_gdsc {
	parent-supply = <&pm855l_s5_level>;
	qcom,vote-parent-supply-voltage;
	status = "ok";
};

&mvs1_gdsc {
	parent-supply = <&pm855l_s5_level>;
	qcom,vote-parent-supply-voltage;
	status = "ok";
};

&npu_core_gdsc {
	status = "ok";
};
#include "sdm855-pinctrl.dtsi"
#include "sdm855-regulator.dtsi"
#include "sdm855-ion.dtsi"
#include "sdm855-bus.dtsi"
#include "sdm855-smp2p.dtsi"
#include "sdm855-coresight.dtsi"
#include "msm-arm-smmu-sdm855.dtsi"
#include "sdm855-qupv3.dtsi"
#include "sdm855-npu.dtsi"
